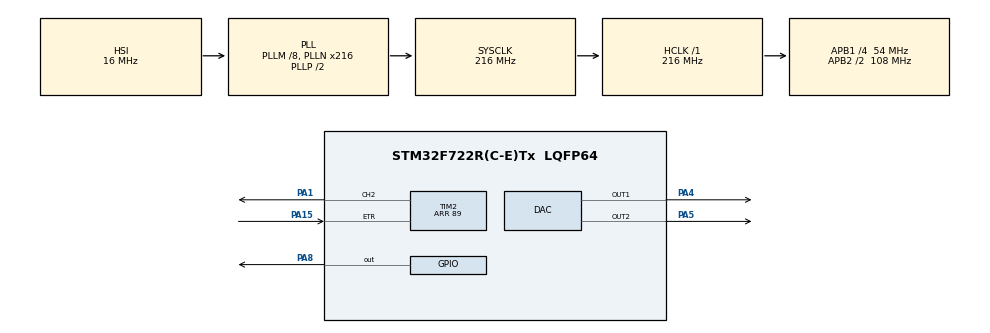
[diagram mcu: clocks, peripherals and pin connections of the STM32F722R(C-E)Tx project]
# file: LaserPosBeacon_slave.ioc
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CORTEX_M7.default_mode_Activation=1
Mcu.Family=STM32F7
Mcu.Name=STM32F722R(C-E)Tx
Mcu.Package=LQFP64
NVIC.PriorityGroup=NVIC_PRIORITYGROUP_4
PA1.Signal=S_TIM2_CH2
PA15.Signal=S_TIM2_CH1_ETR
PA4.Signal=COMP_DAC1_group
PA5.Signal=COMP_DAC2_group
PA8.Signal=GPIO_Output
PH0-OSC_IN.Mode=HSE-External-Oscillator
PH0-OSC_IN.Signal=RCC_OSC_IN
PH1-OSC_OUT.Mode=HSE-External-Oscillator
PH1-OSC_OUT.Signal=RCC_OSC_OUT
ProjectManager.HeapSize=0x200
ProjectManager.StackSize=0x400
ProjectManager.TargetToolchain=STM32CubeIDE
RCC.AHBFreq_Value=216000000
RCC.APB1CLKDivider=RCC_HCLK_DIV4
RCC.APB1Freq_Value=54000000
RCC.APB1TimFreq_Value=108000000
RCC.APB2CLKDivider=RCC_HCLK_DIV2
RCC.APB2Freq_Value=108000000
RCC.APB2TimFreq_Value=216000000
RCC.CortexFreq_Value=216000000
RCC.HCLKFreq_Value=216000000
RCC.HSE_VALUE=25000000
RCC.HSI_VALUE=16000000
RCC.LSE_VALUE=32768
RCC.PLLM=8
RCC.PLLN=216
RCC.SYSCLKFreq_VALUE=216000000
RCC.SYSCLKSource=RCC_SYSCLKSOURCE_PLLCLK
RCC.USBFreq_Value=216000000
RCC.VCOOutputFreq_Value=432000000
SH.COMP_DAC1_group.0=DAC_OUT1,DAC_OUT1
SH.COMP_DAC2_group.0=DAC_OUT2,DAC_OUT2
SH.S_TIM2_CH1_ETR.0=TIM2_ETR,TriggerSource_ETR
SH.S_TIM2_CH2.0=TIM2_CH2,PWM Generation2 CH2
TIM2.Channel-PWM\ Generation2\ CH2=TIM_CHANNEL_2
TIM2.OCPolarity_2=TIM_OCPOLARITY_LOW
TIM2.Period=89
TIM2.Pulse-PWM\ Generation2\ CH2=72
VP_TIM2_VS_ClockSourceINT.Mode=Internal
VP_TIM2_VS_ControllerModeReset.Mode=Reset Mode
board=custom

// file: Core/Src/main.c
/* USER CODE BEGIN Header */
/**
  ******************************************************************************
  * @file           : main.c
  * @brief          : Main program body
  ******************************************************************************
  * @attention
  *
  * Copyright (c) 2026 STMicroelectronics.
  * All rights reserved.
  *
  * This software is licensed under terms that can be found in the LICENSE file
  * in the root directory of this software component.
  * If no LICENSE file comes with this software, it is provided AS-IS.
  *
  ******************************************************************************
  */
/* USER CODE END Header */
#include "main.h"

DAC_HandleTypeDef hdac;

TIM_HandleTypeDef htim2;

void SystemClock_Config(void);
static void MPU_Config(void);
static void MX_GPIO_Init(void);
static void MX_TIM2_Init(void);
static void MX_DAC_Init(void);

int main(void)
{

  /* MPU Configuration--------------------------------------------------------*/
  MPU_Config();

  /* MCU Configuration--------------------------------------------------------*/

  /* Reset of all peripherals, Initializes the Flash interface and the Systick. */
  HAL_Init();

  /* Configure the system clock */
  SystemClock_Config();

  /* Initialize all configured peripherals */
  MX_GPIO_Init();
  MX_TIM2_Init();
  MX_DAC_Init();
  /* USER CODE BEGIN 2 */

  HAL_DAC_Start(&hdac,DAC_CHANNEL_1);
  HAL_DAC_SetValue(&hdac,DAC_CHANNEL_1,DAC_ALIGN_12B_R,2000);

  HAL_DAC_Start(&hdac,DAC_CHANNEL_2);
  HAL_DAC_SetValue(&hdac,DAC_CHANNEL_2,DAC_ALIGN_12B_R,2500);

  HAL_TIM_PWM_Start(&htim2, TIM_CHANNEL_2);
  /* USER CODE END 2 */

  /* Infinite loop */
  while (1)
  {

  }
}

void SystemClock_Config(void)
{
  RCC_OscInitTypeDef RCC_OscInitStruct = {0};
  RCC_ClkInitTypeDef RCC_ClkInitStruct = {0};

  /** Configure the main internal regulator output voltage
  */
  __HAL_RCC_PWR_CLK_ENABLE();
  __HAL_PWR_VOLTAGESCALING_CONFIG(PWR_REGULATOR_VOLTAGE_SCALE1);

  /** Initializes the RCC Oscillators according to the specified parameters
  * in the RCC_OscInitTypeDef structure.
  */
  RCC_OscInitStruct.OscillatorType = RCC_OSCILLATORTYPE_HSI;
  RCC_OscInitStruct.HSIState = RCC_HSI_ON;
  RCC_OscInitStruct.HSICalibrationValue = RCC_HSICALIBRATION_DEFAULT;
  RCC_OscInitStruct.PLL.PLLState = RCC_PLL_ON;
  RCC_OscInitStruct.PLL.PLLSource = RCC_PLLSOURCE_HSI;
  RCC_OscInitStruct.PLL.PLLM = 8;
  RCC_OscInitStruct.PLL.PLLN = 216;
  RCC_OscInitStruct.PLL.PLLP = RCC_PLLP_DIV2;
  RCC_OscInitStruct.PLL.PLLQ = 2;
  if (HAL_RCC_OscConfig(&RCC_OscInitStruct) != HAL_OK)
  {
    Error_Handler();
  }

  /** Activate the Over-Drive mode
  */
  if (HAL_PWREx_EnableOverDrive() != HAL_OK)
  {
    Error_Handler();
  }

  /** Initializes the CPU, AHB and APB buses clocks
  */
  RCC_ClkInitStruct.ClockType = RCC_CLOCKTYPE_HCLK|RCC_CLOCKTYPE_SYSCLK
                              |RCC_CLOCKTYPE_PCLK1|RCC_CLOCKTYPE_PCLK2;
  RCC_ClkInitStruct.SYSCLKSource = RCC_SYSCLKSOURCE_PLLCLK;
  RCC_ClkInitStruct.AHBCLKDivider = RCC_SYSCLK_DIV1;
  RCC_ClkInitStruct.APB1CLKDivider = RCC_HCLK_DIV4;
  RCC_ClkInitStruct.APB2CLKDivider = RCC_HCLK_DIV2;

  if (HAL_RCC_ClockConfig(&RCC_ClkInitStruct, FLASH_LATENCY_7) != HAL_OK)
  {
    Error_Handler();
  }
}

static void MX_DAC_Init(void)
{

  DAC_ChannelConfTypeDef sConfig = {0};

  /** DAC Initialization
  */
  hdac.Instance = DAC;
  if (HAL_DAC_Init(&hdac) != HAL_OK)
  {
    Error_Handler();
  }

  /** DAC channel OUT1 config
  */
  sConfig.DAC_Trigger = DAC_TRIGGER_NONE;
  sConfig.DAC_OutputBuffer = DAC_OUTPUTBUFFER_ENABLE;
  if (HAL_DAC_ConfigChannel(&hdac, &sConfig, DAC_CHANNEL_1) != HAL_OK)
  {
    Error_Handler();
  }

  /** DAC channel OUT2 config
  */
  if (HAL_DAC_ConfigChannel(&hdac, &sConfig, DAC_CHANNEL_2) != HAL_OK)
  {
    Error_Handler();
  }

}

static void MX_TIM2_Init(void)
{

  TIM_ClockConfigTypeDef sClockSourceConfig = {0};
  TIM_SlaveConfigTypeDef sSlaveConfig = {0};
  TIM_MasterConfigTypeDef sMasterConfig = {0};
  TIM_OC_InitTypeDef sConfigOC = {0};

  htim2.Instance = TIM2;
  htim2.Init.Prescaler = 0;
  htim2.Init.CounterMode = TIM_COUNTERMODE_UP;
  htim2.Init.Period = 141;
  htim2.Init.ClockDivision = TIM_CLOCKDIVISION_DIV1;
  htim2.Init.AutoReloadPreload = TIM_AUTORELOAD_PRELOAD_DISABLE;
  if (HAL_TIM_Base_Init(&htim2) != HAL_OK)
  {
    Error_Handler();
  }
  sClockSourceConfig.ClockSource = TIM_CLOCKSOURCE_INTERNAL;
  if (HAL_TIM_ConfigClockSource(&htim2, &sClockSourceConfig) != HAL_OK)
  {
    Error_Handler();
  }
  if (HAL_TIM_PWM_Init(&htim2) != HAL_OK)
  {
    Error_Handler();
  }
  sSlaveConfig.SlaveMode = TIM_SLAVEMODE_RESET;
  sSlaveConfig.InputTrigger = TIM_TS_ETRF;
  sSlaveConfig.TriggerPolarity = TIM_TRIGGERPOLARITY_NONINVERTED;
  sSlaveConfig.TriggerPrescaler = TIM_TRIGGERPRESCALER_DIV1;
  sSlaveConfig.TriggerFilter = 0;
  if (HAL_TIM_SlaveConfigSynchro(&htim2, &sSlaveConfig) != HAL_OK)
  {
    Error_Handler();
  }
  sMasterConfig.MasterOutputTrigger = TIM_TRGO_RESET;
  sMasterConfig.MasterSlaveMode = TIM_MASTERSLAVEMODE_DISABLE;
  if (HAL_TIMEx_MasterConfigSynchronization(&htim2, &sMasterConfig) != HAL_OK)
  {
    Error_Handler();
  }
  sConfigOC.OCMode = TIM_OCMODE_PWM1;
  sConfigOC.Pulse = 112;
  sConfigOC.OCPolarity = TIM_OCPOLARITY_LOW;
  sConfigOC.OCFastMode = TIM_OCFAST_DISABLE;
  if (HAL_TIM_PWM_ConfigChannel(&htim2, &sConfigOC, TIM_CHANNEL_2) != HAL_OK)
  {
    Error_Handler();
  }
  HAL_TIM_MspPostInit(&htim2);

}

static void MX_GPIO_Init(void)
{
  GPIO_InitTypeDef GPIO_InitStruct = {0};

  /* GPIO Ports Clock Enable */
  __HAL_RCC_GPIOH_CLK_ENABLE();
  __HAL_RCC_GPIOA_CLK_ENABLE();

  /*Configure GPIO pin Output Level */
  HAL_GPIO_WritePin(GPIOA, GPIO_PIN_8, GPIO_PIN_RESET);

  /*Configure GPIO pin : PA8 */
  GPIO_InitStruct.Pin = GPIO_PIN_8;
  GPIO_InitStruct.Mode = GPIO_MODE_OUTPUT_PP;
  GPIO_InitStruct.Pull = GPIO_NOPULL;
  GPIO_InitStruct.Speed = GPIO_SPEED_FREQ_LOW;
  HAL_GPIO_Init(GPIOA, &GPIO_InitStruct);

}

 /* MPU Configuration */

void MPU_Config(void)
{
  MPU_Region_InitTypeDef MPU_InitStruct = {0};

  /* Disables the MPU */
  HAL_MPU_Disable();

  /** Initializes and configures the Region and the memory to be protected
  */
  MPU_InitStruct.Enable = MPU_REGION_ENABLE;
  MPU_InitStruct.Number = MPU_REGION_NUMBER0;
  MPU_InitStruct.BaseAddress = 0x0;
  MPU_InitStruct.Size = MPU_REGION_SIZE_4GB;
  MPU_InitStruct.SubRegionDisable = 0x87;
  MPU_InitStruct.TypeExtField = MPU_TEX_LEVEL0;
  MPU_InitStruct.AccessPermission = MPU_REGION_NO_ACCESS;
  MPU_InitStruct.DisableExec = MPU_INSTRUCTION_ACCESS_DISABLE;
  MPU_InitStruct.IsShareable = MPU_ACCESS_SHAREABLE;
  MPU_InitStruct.IsCacheable = MPU_ACCESS_NOT_CACHEABLE;
  MPU_InitStruct.IsBufferable = MPU_ACCESS_NOT_BUFFERABLE;

  HAL_MPU_ConfigRegion(&MPU_InitStruct);
  /* Enables the MPU */
  HAL_MPU_Enable(MPU_PRIVILEGED_DEFAULT);

}

void Error_Handler(void)
{
  __disable_irq();
  while (1)
  {
  }
}
